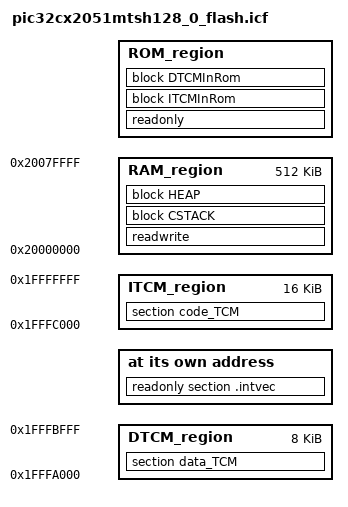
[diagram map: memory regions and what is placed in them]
/* ---------------------------------------------------------------------------- */
/*                Microchip Microcontroller Software Support                    */
/*                       SAM Software Package License                           */
/* ---------------------------------------------------------------------------- */
/* Copyright (c) %copyright_year%, Microchip Technology Inc.                    */
/*                                                                              */
/* All rights reserved.                                                         */
/*                                                                              */
/* Redistribution and use in source and binary forms, with or without           */
/* modification, are permitted provided that the following condition is met:    */
/*                                                                              */
/* - Redistributions of source code must retain the above copyright notice,     */
/* this list of conditions and the disclaimer below.                            */
/*                                                                              */
/* Microchip's name may not be used to endorse or promote products derived from */
/* this software without specific prior written permission.                     */
/*                                                                              */
/* DISCLAIMER:  THIS SOFTWARE IS PROVIDED BY MICROCHIP "AS IS" AND ANY EXPRESS  */
/* OR IMPLIED WARRANTIES, INCLUDING, BUT NOT LIMITED TO, THE IMPLIED WARRANTIES */
/* OF MERCHANTABILITY, FITNESS FOR A PARTICULAR PURPOSE AND NON-INFRINGEMENT    */
/* ARE DISCLAIMED. IN NO EVENT SHALL MICROCHIP BE LIABLE FOR ANY DIRECT,        */
/* INDIRECT, INCIDENTAL, SPECIAL, EXEMPLARY, OR CONSEQUENTIAL DAMAGES           */
/* (INCLUDING, BUT NOT LIMITED TO, PROCUREMENT OF SUBSTITUTE GOODS OR SERVICES; */
/* LOSS OF USE, DATA, OR PROFITS; OR BUSINESS INTERRUPTION) HOWEVER CAUSED AND  */
/* ON ANY THEORY OF LIABILITY, WHETHER IN CONTRACT, STRICT LIABILITY, OR TORT   */
/* (INCLUDING NEGLIGENCE OR OTHERWISE) ARISING IN ANY WAY OUT OF THE USE OF     */
/* THIS SOFTWARE, EVEN IF ADVISED OF THE POSSIBILITY OF SUCH DAMAGE.            */
/* ---------------------------------------------------------------------------- */

/*###ICF### Section handled by ICF editor, don't touch! ****/
/*-Editor annotation file-*/
/* IcfEditorFile="$TOOLKIT_DIR$\config\ide\IcfEditor\cortex_v1_0.xml" */

// 2MB FLASH (0x200000)
if (!isdefinedsymbol(MBED_APP_START)) { define symbol MBED_APP_START = 0x01000000; }
if (!isdefinedsymbol(MBED_APP_SIZE)) { define symbol MBED_APP_SIZE = 0x200000; }
if (!isdefinedsymbol(MBED_CONF_TARGET_BOOT_STACK_SIZE)) { define symbol MBED_CONF_TARGET_BOOT_STACK_SIZE = 0x400; }

// 512KB RAM (0x80000)

/*-Specials-*/
define symbol __ICFEDIT_intvec_start__     = MBED_APP_START;
/*-Memory Regions-*/
define symbol __ICFEDIT_region_RAM_start__ = 0x20000000;
define symbol __ICFEDIT_region_RAM_end__   = 0x2007FFFF;
define symbol __ICFEDIT_region_ROM_start__ = MBED_APP_START;
define symbol __ICFEDIT_region_ROM_end__   = MBED_APP_START + MBED_APP_SIZE - 1;
/*-Sizes-*/
define symbol __ICFEDIT_size_cstack__      = MBED_CONF_TARGET_BOOT_STACK_SIZE;
if (!isdefinedsymbol(__ICFEDIT_size_heap__)) {
define symbol __ICFEDIT_size_heap__        = 0x400;
}
/* TCM regions */
define symbol __ICFEDIT_region_DTCM_start__ = 0x1FFFA000;
define symbol __ICFEDIT_region_DTCM_end__   = 0x1FFFBFFF;
define symbol __ICFEDIT_region_ITCM_start__ = 0x1FFFC000;
define symbol __ICFEDIT_region_ITCM_end__   = 0x1FFFFFFF;
/**** End of ICF editor section. ###ICF###*/

define memory mem with size = 4G;
define region RAM_region    = mem:[from __ICFEDIT_region_RAM_start__ to __ICFEDIT_region_RAM_end__];
define region ROM_region    = mem:[from __ICFEDIT_region_ROM_start__ to __ICFEDIT_region_ROM_end__];
define region ITCM_region   = mem:[from __ICFEDIT_region_ITCM_start__ to __ICFEDIT_region_ITCM_end__];
define region DTCM_region   = mem:[from __ICFEDIT_region_DTCM_start__ to __ICFEDIT_region_DTCM_end__];

/* Place the initializer sections in a block each */
define block ITCMInRom with alignment = 8 { section code_TCM_init };
define block DTCMInRom with alignment = 8 { section data_TCM_init };

define block CSTACK with alignment = 8, size = __ICFEDIT_size_cstack__ { };
define block HEAP   with alignment = 8, size = __ICFEDIT_size_heap__   { };

initialize by copy { readwrite };
initialize manually { section code_TCM, section data_TCM };

do not initialize  { section .noinit };

place at address mem:__ICFEDIT_intvec_start__ { readonly section .intvec };
place in ROM_region                           { readonly, block ITCMInRom, , block DTCMInRom };
place in RAM_region                           { readwrite, block CSTACK, block HEAP };
place in ITCM_region                          { section code_TCM };
place in DTCM_region                          { section data_TCM };
